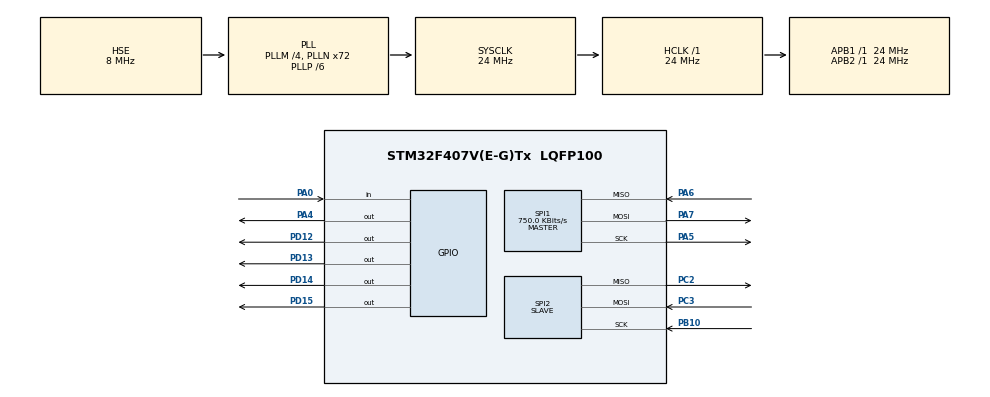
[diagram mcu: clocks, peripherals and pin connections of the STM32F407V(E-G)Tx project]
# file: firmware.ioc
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Mcu.Family=STM32F4
Mcu.Name=STM32F407V(E-G)Tx
Mcu.Package=LQFP100
NVIC.PriorityGroup=NVIC_PRIORITYGROUP_4
NVIC.SPI2_IRQn=true\:0\:0\:false\:false\:true\:true\:true
PA0-WKUP.Signal=GPIO_Input
PA13.Mode=Serial_Wire
PA13.Signal=SYS_JTMS-SWDIO
PA14.Mode=Serial_Wire
PA14.Signal=SYS_JTCK-SWCLK
PA4.Signal=GPIO_Output
PA5.Mode=Full_Duplex_Master
PA5.Signal=SPI1_SCK
PA6.Mode=Full_Duplex_Master
PA6.Signal=SPI1_MISO
PA7.Mode=Full_Duplex_Master
PA7.Signal=SPI1_MOSI
PB10.Mode=Full_Duplex_Slave
PB10.Signal=SPI2_SCK
PC14-OSC32_IN.Mode=LSE-External-Oscillator
PC14-OSC32_IN.Signal=RCC_OSC32_IN
PC15-OSC32_OUT.Mode=LSE-External-Oscillator
PC15-OSC32_OUT.Signal=RCC_OSC32_OUT
PC2.Mode=Full_Duplex_Slave
PC2.Signal=SPI2_MISO
PC3.Mode=Full_Duplex_Slave
PC3.Signal=SPI2_MOSI
PD12.Signal=GPIO_Output
PD13.Signal=GPIO_Output
PD14.Signal=GPIO_Output
PD15.Signal=GPIO_Output
PH0-OSC_IN.Mode=HSE-External-Oscillator
PH0-OSC_IN.Signal=RCC_OSC_IN
PH1-OSC_OUT.Mode=HSE-External-Oscillator
PH1-OSC_OUT.Signal=RCC_OSC_OUT
ProjectManager.HeapSize=0x200
ProjectManager.StackSize=0x400
ProjectManager.TargetToolchain=STM32CubeIDE
RCC.48MHZClocksFreq_Value=36000000
RCC.AHBFreq_Value=24000000
RCC.APB1Freq_Value=24000000
RCC.APB1TimFreq_Value=24000000
RCC.APB2Freq_Value=24000000
RCC.APB2TimFreq_Value=24000000
RCC.CortexFreq_Value=24000000
RCC.HCLKFreq_Value=24000000
RCC.HSE_VALUE=8000000
RCC.HSI_VALUE=16000000
RCC.PLLM=4
RCC.PLLN=72
RCC.PLLP=RCC_PLLP_DIV6
RCC.PLLSourceVirtual=RCC_PLLSOURCE_HSE
RCC.SYSCLKFreq_VALUE=24000000
RCC.SYSCLKSource=RCC_SYSCLKSOURCE_PLLCLK
RCC.VCOOutputFreq_Value=144000000
SPI1.BaudRatePrescaler=SPI_BAUDRATEPRESCALER_32
SPI1.CalculateBaudRate=750.0 KBits/s
SPI1.Direction=SPI_DIRECTION_2LINES
SPI1.Mode=SPI_MODE_MASTER
SPI1.VirtualType=VM_MASTER
SPI2.Direction=SPI_DIRECTION_2LINES
SPI2.Mode=SPI_MODE_SLAVE
SPI2.VirtualType=VM_SLAVE
board=custom

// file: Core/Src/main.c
/* USER CODE BEGIN Header */
/**
  ******************************************************************************
  * @file           : main.c
  * @brief          : Main program body
  ******************************************************************************
  * @attention
  *
  * <h2><center>&copy; Copyright (c) 2021 STMicroelectronics.
  * All rights reserved.</center></h2>
  *
  * This software component is licensed by ST under BSD 3-Clause license,
  * the "License"; You may not use this file except in compliance with the
  * License. You may obtain a copy of the License at:
  *                        opensource.org/licenses/BSD-3-Clause
  *
  ******************************************************************************
  */
/* USER CODE END Header */
#include "main.h"
#include "spi.h"
#include "gpio.h"

/* USER CODE BEGIN PV */
GPIO_PinState BTN_State = GPIO_PIN_RESET;
uint16_t readbackError_hspi1 = 0;
uint8_t  send_hspi1          = 0x00;
uint8_t  receive_hspi1       = 0x00;
uint16_t readbackError_hspi2 = 0;
uint8_t  send_hspi2          = 0x00;
uint8_t  receive_hspi2       = 0x00;
/* USER CODE END PV */

void SystemClock_Config(void);

int main(void)
{

  /* MCU Configuration--------------------------------------------------------*/

  /* Reset of all peripherals, Initializes the Flash interface and the Systick. */
  HAL_Init();

  /* Configure the system clock */
  SystemClock_Config();

  /* Initialize all configured peripherals */
  MX_GPIO_Init();
  MX_SPI1_Init();
  MX_SPI2_Init();
  /* USER CODE BEGIN 2 */
  HAL_GPIO_WritePin(GPIOA, GPIO_PIN_4, GPIO_PIN_SET);
  HAL_SPI_TransmitReceive_IT(&hspi2, &send_hspi2, &receive_hspi2, 1);
  /* USER CODE END 2 */

  /* Infinite loop */
  while (1)
  {
    BTN_State = HAL_GPIO_ReadPin(GPIOA, GPIO_PIN_0);
    HAL_Delay(100);
    if(BTN_State==GPIO_PIN_SET)
    {
      static uint8_t receive_hspi1_next = 0x00;
      while (1)
      {
        HAL_GPIO_WritePin(GPIOA, GPIO_PIN_4, GPIO_PIN_RESET);
        HAL_SPI_TransmitReceive(&hspi1, &send_hspi1, &receive_hspi1, 1, 1);
        HAL_GPIO_WritePin(GPIOA, GPIO_PIN_4, GPIO_PIN_SET);
        if(receive_hspi1 != receive_hspi1_next)
        {
          ++readbackError_hspi1;
        }
        receive_hspi1_next = receive_hspi1 + 1;
        ++send_hspi1;
        HAL_GPIO_TogglePin(GPIOD, GPIO_PIN_12);
        HAL_Delay(500);
      }
    }

  }
}

/**
  * @brief  Tx and Rx Transfer completed callback.
  * @param  hspi pointer to a SPI_HandleTypeDef structure that contains
  *               the configuration information for SPI module.
  * @retval None
  */
void HAL_SPI_TxRxCpltCallback(SPI_HandleTypeDef *hspi)
{
  /* Prevent unused argument(s) compilation warning */
  UNUSED(hspi);
  //
  static uint8_t receive_hspi2_next = 0x00;
  if(receive_hspi2 != receive_hspi2_next)
  {
    ++readbackError_hspi2;
  }
  receive_hspi2_next = receive_hspi2 + 1;
  ++send_hspi2;
  HAL_SPI_TransmitReceive_IT(&hspi2, &send_hspi2, &receive_hspi2, 1);
  HAL_GPIO_TogglePin(GPIOD, GPIO_PIN_13);
}

void SystemClock_Config(void)
{
  RCC_OscInitTypeDef RCC_OscInitStruct = {0};
  RCC_ClkInitTypeDef RCC_ClkInitStruct = {0};

  /** Configure the main internal regulator output voltage
  */
  __HAL_RCC_PWR_CLK_ENABLE();
  __HAL_PWR_VOLTAGESCALING_CONFIG(PWR_REGULATOR_VOLTAGE_SCALE1);
  /** Initializes the RCC Oscillators according to the specified parameters
  * in the RCC_OscInitTypeDef structure.
  */
  RCC_OscInitStruct.OscillatorType = RCC_OSCILLATORTYPE_HSE;
  RCC_OscInitStruct.HSEState = RCC_HSE_ON;
  RCC_OscInitStruct.PLL.PLLState = RCC_PLL_ON;
  RCC_OscInitStruct.PLL.PLLSource = RCC_PLLSOURCE_HSE;
  RCC_OscInitStruct.PLL.PLLM = 4;
  RCC_OscInitStruct.PLL.PLLN = 72;
  RCC_OscInitStruct.PLL.PLLP = RCC_PLLP_DIV6;
  RCC_OscInitStruct.PLL.PLLQ = 4;
  if (HAL_RCC_OscConfig(&RCC_OscInitStruct) != HAL_OK)
  {
    Error_Handler();
  }
  /** Initializes the CPU, AHB and APB buses clocks
  */
  RCC_ClkInitStruct.ClockType = RCC_CLOCKTYPE_HCLK|RCC_CLOCKTYPE_SYSCLK
                              |RCC_CLOCKTYPE_PCLK1|RCC_CLOCKTYPE_PCLK2;
  RCC_ClkInitStruct.SYSCLKSource = RCC_SYSCLKSOURCE_PLLCLK;
  RCC_ClkInitStruct.AHBCLKDivider = RCC_SYSCLK_DIV1;
  RCC_ClkInitStruct.APB1CLKDivider = RCC_HCLK_DIV1;
  RCC_ClkInitStruct.APB2CLKDivider = RCC_HCLK_DIV1;

  if (HAL_RCC_ClockConfig(&RCC_ClkInitStruct, FLASH_LATENCY_0) != HAL_OK)
  {
    Error_Handler();
  }
}

void Error_Handler(void)
{
}

/************************ (C) COPYRIGHT STMicroelectronics *****END OF FILE****/
